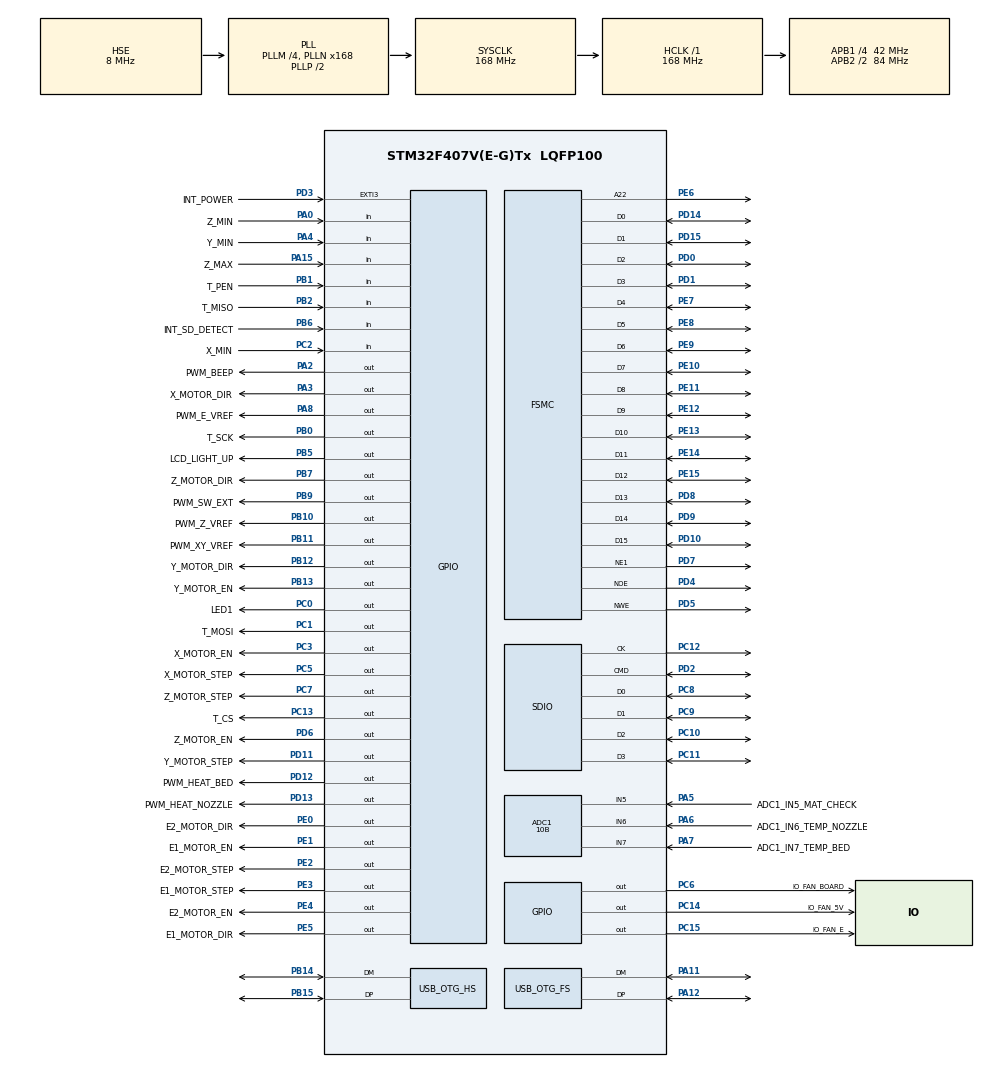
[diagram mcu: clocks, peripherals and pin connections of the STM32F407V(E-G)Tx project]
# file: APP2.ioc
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ADC1.Channel-0\#ChannelRegularConversion=ADC_CHANNEL_5
ADC1.EnableAnalogWatchDog=false
ADC1.NbrOfConversionFlag=1
ADC1.Rank-0\#ChannelRegularConversion=1
ADC1.Resolution=ADC_RESOLUTION_10B
ADC1.SamplingTime-0\#ChannelRegularConversion=ADC_SAMPLETIME_3CYCLES
ADC1.ScanConvMode=ENABLE
ADC1.master=1
Dma.Request0=SDIO_RX
Dma.Request1=SDIO_TX
Dma.SDIO_RX.0.Direction=DMA_PERIPH_TO_MEMORY
Dma.SDIO_RX.0.FIFOMode=DMA_FIFOMODE_ENABLE
Dma.SDIO_RX.0.FIFOThreshold=DMA_FIFO_THRESHOLD_FULL
Dma.SDIO_RX.0.Instance=DMA2_Stream3
Dma.SDIO_RX.0.MemBurst=DMA_MBURST_INC4
Dma.SDIO_RX.0.MemDataAlignment=DMA_MDATAALIGN_WORD
Dma.SDIO_RX.0.MemInc=DMA_MINC_ENABLE
Dma.SDIO_RX.0.Mode=DMA_PFCTRL
Dma.SDIO_RX.0.PeriphBurst=DMA_PBURST_INC4
Dma.SDIO_RX.0.PeriphDataAlignment=DMA_PDATAALIGN_WORD
Dma.SDIO_RX.0.PeriphInc=DMA_PINC_DISABLE
Dma.SDIO_RX.0.Priority=DMA_PRIORITY_LOW
Dma.SDIO_TX.1.Direction=DMA_MEMORY_TO_PERIPH
Dma.SDIO_TX.1.FIFOMode=DMA_FIFOMODE_ENABLE
Dma.SDIO_TX.1.FIFOThreshold=DMA_FIFO_THRESHOLD_FULL
Dma.SDIO_TX.1.Instance=DMA2_Stream6
Dma.SDIO_TX.1.MemBurst=DMA_MBURST_INC4
Dma.SDIO_TX.1.MemDataAlignment=DMA_MDATAALIGN_WORD
Dma.SDIO_TX.1.MemInc=DMA_MINC_ENABLE
Dma.SDIO_TX.1.Mode=DMA_PFCTRL
Dma.SDIO_TX.1.PeriphBurst=DMA_PBURST_INC4
Dma.SDIO_TX.1.PeriphDataAlignment=DMA_PDATAALIGN_WORD
Dma.SDIO_TX.1.PeriphInc=DMA_PINC_DISABLE
Dma.SDIO_TX.1.Priority=DMA_PRIORITY_LOW
FATFS.BSP.number=1
FATFS._CODE_PAGE=936
FATFS._FS_LOCK=16
FATFS._FS_NORTC=0
FATFS._MAX_LFN=64
FATFS._USE_LFN=3
FATFS0.BSP.STBoard=false
FATFS0.BSP.i2caddr=0
FATFS0.BSP.i2creg=0
FATFS0.BSP.instance=PB6
FATFS0.BSP.ip=GPIO
FATFS0.BSP.mode=Input
FATFS0.BSP.name=Detect_SDIO
FSMC.BusTurnAroundDuration1=0
FSMC.DataSetupTime1=60
FSMC.ExtendedAddressSetupTime1=9
FSMC.ExtendedBusTurnAroundDuration1=0
FSMC.ExtendedDataSetupTime1=8
FSMC.ExtendedMode1=FSMC_EXTENDED_MODE_ENABLE
Mcu.Family=STM32F4
Mcu.Name=STM32F407V(E-G)Tx
Mcu.Package=LQFP100
NVIC.ADC_IRQn=true\:0\:0\:false\:true\:true\:5
NVIC.DMA2_Stream3_IRQn=true\:8\:0\:true\:true\:true\:9
NVIC.DMA2_Stream6_IRQn=true\:8\:0\:true\:true\:true\:11
NVIC.EXTI3_IRQn=true\:0\:0\:false\:true\:true\:4
NVIC.FLASH_IRQn=true\:0\:0\:false\:true\:true\:2
NVIC.FPU_IRQn=true\:0\:0\:false\:true\:true\:15
NVIC.OTG_FS_IRQn=true\:7\:0\:true\:true\:true\:10
NVIC.OTG_HS_EP1_IN_IRQn=true\:7\:0\:true\:true\:true\:13
NVIC.OTG_HS_EP1_OUT_IRQn=true\:7\:0\:true\:true\:true\:12
NVIC.OTG_HS_IRQn=true\:7\:0\:true\:true\:true\:14
NVIC.PVD_IRQn=true\:0\:0\:false\:true\:true\:1
NVIC.PriorityGroup=NVIC_PRIORITYGROUP_4
NVIC.RCC_IRQn=true\:0\:0\:false\:true\:true\:3
NVIC.SDIO_IRQn=true\:7\:0\:true\:true\:true\:8
NVIC.TIM1_UP_TIM10_IRQn=true\:0\:0\:false\:false\:true
NVIC.TimeBase=TIM1_UP_TIM10_IRQn
NVIC.TimeBaseIP=TIM1
PA0-WKUP.GPIO_Label=Z_MIN
PA0-WKUP.GPIO_PuPd=GPIO_PULLUP
PA0-WKUP.Signal=GPIO_Input
PA11.GPIO_Speed=GPIO_SPEED_FREQ_VERY_HIGH
PA11.Mode=Host_Only
PA11.Signal=USB_OTG_FS_DM
PA12.GPIO_Speed=GPIO_SPEED_FREQ_VERY_HIGH
PA12.Mode=Host_Only
PA12.Signal=USB_OTG_FS_DP
PA15.GPIO_Label=Z_MAX
PA15.GPIO_PuPd=GPIO_PULLUP
PA15.Signal=GPIO_Input
PA2.GPIO_Label=PWM_BEEP
PA2.Signal=GPIO_Output
PA3.GPIO_Label=X_MOTOR_DIR
PA3.Signal=GPIO_Output
PA4.GPIO_Label=Y_MIN
PA4.GPIO_PuPd=GPIO_PULLUP
PA4.Signal=GPIO_Input
PA5.GPIO_Label=ADC1_IN5_MAT_CHECK
PA5.Signal=ADCx_IN5
PA6.GPIO_Label=ADC1_IN6_TEMP_NOZZLE
PA6.Signal=ADCx_IN6
PA7.GPIO_Label=ADC1_IN7_TEMP_BED
PA7.Signal=ADCx_IN7
PA8.GPIO_Label=PWM_E_VREF
PA8.Signal=GPIO_Output
PB0.GPIO_Label=T_SCK
PB0.Signal=GPIO_Output
PB1.GPIO_Label=T_PEN
PB1.Signal=GPIO_Input
PB10.GPIO_Label=PWM_Z_VREF
PB10.Signal=GPIO_Output
PB11.GPIO_Label=PWM_XY_VREF
PB11.Signal=GPIO_Output
PB12.GPIO_Label=Y_MOTOR_DIR
PB12.Signal=GPIO_Output
PB13.GPIO_Label=Y_MOTOR_EN
PB13.Signal=GPIO_Output
PB14.Mode=Host_FS
PB14.Signal=USB_OTG_HS_DM
PB15.Mode=Host_FS
PB15.Signal=USB_OTG_HS_DP
PB2.GPIO_Label=T_MISO
PB2.Signal=GPIO_Input
PB5.GPIO_Label=LCD_LIGHT_UP
PB5.GPIO_PuPd=GPIO_PULLUP
PB5.Signal=GPIO_Output
PB6.GPIO_Label=INT_SD_DETECT
PB6.GPIO_PuPd=GPIO_PULLUP
PB6.Signal=GPIO_Input
PB7.GPIO_Label=Z_MOTOR_DIR
PB7.Signal=GPIO_Output
PB9.GPIO_Label=PWM_SW_EXT
PB9.Signal=GPIO_Output
PC0.GPIO_Label=LED1
PC0.GPIO_PuPd=GPIO_PULLUP
PC0.Signal=GPIO_Output
PC1.GPIO_Label=T_MOSI
PC1.Signal=GPIO_Output
PC10.GPIO_PuPd=GPIO_PULLUP
PC10.GPIO_Speed_High_Default=GPIO_SPEED_FREQ_HIGH
PC10.Mode=SD_4_bits_Wide_bus
PC10.Signal=SDIO_D2
PC11.GPIO_PuPd=GPIO_PULLUP
PC11.GPIO_Speed_High_Default=GPIO_SPEED_FREQ_HIGH
PC11.Mode=SD_4_bits_Wide_bus
PC11.Signal=SDIO_D3
PC12.GPIO_Speed_High_Default=GPIO_SPEED_FREQ_HIGH
PC12.Mode=SD_4_bits_Wide_bus
PC12.Signal=SDIO_CK
PC13-ANTI_TAMP.GPIO_Label=T_CS
PC13-ANTI_TAMP.Signal=GPIO_Output
PC14-OSC32_IN.GPIO_Label=IO_FAN_5V
PC14-OSC32_IN.Signal=GPIO_Output
PC15-OSC32_OUT.GPIO_Label=IO_FAN_E
PC15-OSC32_OUT.Signal=GPIO_Output
PC2.GPIO_Label=X_MIN
PC2.GPIO_PuPd=GPIO_PULLUP
PC2.Signal=GPIO_Input
PC3.GPIO_Label=X_MOTOR_EN
PC3.Signal=GPIO_Output
PC5.GPIO_Label=X_MOTOR_STEP
PC5.Signal=GPIO_Output
PC6.GPIO_Label=IO_FAN_BOARD
PC6.Signal=GPIO_Output
PC7.GPIO_Label=Z_MOTOR_STEP
PC7.Signal=GPIO_Output
PC8.GPIO_PuPd=GPIO_PULLUP
PC8.GPIO_Speed_High_Default=GPIO_SPEED_FREQ_HIGH
PC8.Mode=SD_4_bits_Wide_bus
PC8.Signal=SDIO_D0
PC9.GPIO_PuPd=GPIO_PULLUP
PC9.GPIO_Speed_High_Default=GPIO_SPEED_FREQ_HIGH
PC9.Mode=SD_4_bits_Wide_bus
PC9.Signal=SDIO_D1
PD0.Mode=16b-d1
PD0.Signal=FSMC_D2
PD1.Mode=16b-d1
PD1.Signal=FSMC_D3
PD10.Mode=16b-d1
PD10.Signal=FSMC_D15
PD11.GPIO_Label=Y_MOTOR_STEP
PD11.Signal=GPIO_Output
PD12.GPIO_Label=PWM_HEAT_BED
PD12.Signal=GPIO_Output
PD13.GPIO_Label=PWM_HEAT_NOZZLE
PD13.Signal=GPIO_Output
PD14.Mode=16b-d1
PD14.Signal=FSMC_D0
PD15.Mode=16b-d1
PD15.Signal=FSMC_D1
PD2.GPIO_PuPd=GPIO_PULLUP
PD2.GPIO_Speed_High_Default=GPIO_SPEED_FREQ_HIGH
PD2.Mode=SD_4_bits_Wide_bus
PD2.Signal=SDIO_CMD
PD3.GPIO_Label=INT_POWER
PD3.GPIO_PuPd=GPIO_PULLUP
PD3.Signal=GPXTI3
PD4.Mode=Lcd1
PD4.Signal=FSMC_NOE
PD5.Mode=Lcd1
PD5.Signal=FSMC_NWE
PD6.GPIO_Label=Z_MOTOR_EN
PD6.Signal=GPIO_Output
PD7.Mode=NorPsramChipSelect1_1
PD7.Signal=FSMC_NE1
PD8.Mode=16b-d1
PD8.Signal=FSMC_D13
PD9.Mode=16b-d1
PD9.Signal=FSMC_D14
PE0.GPIO_Label=E2_MOTOR_DIR
PE0.Signal=GPIO_Output
PE1.GPIO_Label=E1_MOTOR_EN
PE1.Signal=GPIO_Output
PE10.Mode=16b-d1
PE10.Signal=FSMC_D7
PE11.Mode=16b-d1
PE11.Signal=FSMC_D8
PE12.Mode=16b-d1
PE12.Signal=FSMC_D9
PE13.Mode=16b-d1
PE13.Signal=FSMC_D10
PE14.Mode=16b-d1
PE14.Signal=FSMC_D11
PE15.Mode=16b-d1
PE15.Signal=FSMC_D12
PE2.GPIO_Label=E2_MOTOR_STEP
PE2.Signal=GPIO_Output
PE3.GPIO_Label=E1_MOTOR_STEP
PE3.Signal=GPIO_Output
PE4.GPIO_Label=E2_MOTOR_EN
PE4.Signal=GPIO_Output
PE5.GPIO_Label=E1_MOTOR_DIR
PE5.Signal=GPIO_Output
PE6.Mode=A22_1
PE6.Signal=FSMC_A22
PE7.Mode=16b-d1
PE7.Signal=FSMC_D4
PE8.Mode=16b-d1
PE8.Signal=FSMC_D5
PE9.Mode=16b-d1
PE9.Signal=FSMC_D6
PH0-OSC_IN.Mode=HSE-External-Oscillator
PH0-OSC_IN.Signal=RCC_OSC_IN
PH1-OSC_OUT.Mode=HSE-External-Oscillator
PH1-OSC_OUT.Signal=RCC_OSC_OUT
ProjectManager.HeapSize=0x2000
ProjectManager.StackSize=0x2000
ProjectManager.TargetToolchain=MDK-ARM V5
RCC.48MHZClocksFreq_Value=48000000
RCC.AHBFreq_Value=168000000
RCC.APB1CLKDivider=RCC_HCLK_DIV4
RCC.APB1Freq_Value=42000000
RCC.APB1TimFreq_Value=84000000
RCC.APB2CLKDivider=RCC_HCLK_DIV2
RCC.APB2Freq_Value=84000000
RCC.APB2TimFreq_Value=168000000
RCC.CortexFreq_Value=168000000
RCC.HCLKFreq_Value=168000000
RCC.HSE_VALUE=8000000
RCC.HSI_VALUE=16000000
RCC.LSE_VALUE=32768
RCC.PLLM=4
RCC.PLLN=168
RCC.PLLQ=7
RCC.SYSCLKFreq_VALUE=168000000
RCC.SYSCLKSource=RCC_SYSCLKSOURCE_PLLCLK
RCC.VCOOutputFreq_Value=336000000
SDIO.BusWide=SDIO_BUS_WIDE_1B
SDIO.ClockDiv=1
SDIO.WideMode=SDIO_BUS_WIDE_4B
SH.ADCx_IN5.0=ADC1_IN5,IN5
SH.ADCx_IN6.0=ADC1_IN6,IN6
SH.ADCx_IN7.0=ADC1_IN7,IN7
USB_HOST.USBH_HandleTypeDef-MSC_FS=hUsbHostFS
USB_HOST.USBH_PROCESS_STACK_SIZE-MSC_FS=640
USB_HOST.VirtualModeFS=Msc
USB_OTG_FS.phy_itface=HCD_PHY_EMBEDDED
USB_OTG_HS.VirtualMode-Host_FS=Host_FS
USB_OTG_HS.dma_enable-Host_FS=ENABLE
VP_CRC_VS_CRC.Mode=CRC_Activate
VP_FATFS_VS_SDIO.Mode=SDIO
VP_FATFS_VS_USB.Mode=USB
VP_SYS_VS_tim1.Mode=TIM1
VP_USB_HOST_VS_USB_HOST_MSC_FS.Mode=MSC_FS
board=APP2

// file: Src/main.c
/**
  ******************************************************************************
  * File Name          : main.c
  * Description        : Main program body
  ******************************************************************************
  *
  * COPYRIGHT(c) 2016 STMicroelectronics
  *
  * Redistribution and use in source and binary forms, with or without modification,
  * are permitted provided that the following conditions are met:
  *   1. Redistributions of source code must retain the above copyright notice,
  *      this list of conditions and the following disclaimer.
  *   2. Redistributions in binary form must reproduce the above copyright notice,
  *      this list of conditions and the following disclaimer in the documentation
  *      and/or other materials provided with the distribution.
  *   3. Neither the name of STMicroelectronics nor the names of its contributors
  *      may be used to endorse or promote products derived from this software
  *      without specific prior written permission.
  *
  * THIS SOFTWARE IS PROVIDED BY THE COPYRIGHT HOLDERS AND CONTRIBUTORS "AS IS"
  * AND ANY EXPRESS OR IMPLIED WARRANTIES, INCLUDING, BUT NOT LIMITED TO, THE
  * IMPLIED WARRANTIES OF MERCHANTABILITY AND FITNESS FOR A PARTICULAR PURPOSE ARE
  * DISCLAIMED. IN NO EVENT SHALL THE COPYRIGHT HOLDER OR CONTRIBUTORS BE LIABLE
  * FOR ANY DIRECT, INDIRECT, INCIDENTAL, SPECIAL, EXEMPLARY, OR CONSEQUENTIAL
  * DAMAGES (INCLUDING, BUT NOT LIMITED TO, PROCUREMENT OF SUBSTITUTE GOODS OR
  * SERVICES; LOSS OF USE, DATA, OR PROFITS; OR BUSINESS INTERRUPTION) HOWEVER
  * CAUSED AND ON ANY THEORY OF LIABILITY, WHETHER IN CONTRACT, STRICT LIABILITY,
  * OR TORT (INCLUDING NEGLIGENCE OR OTHERWISE) ARISING IN ANY WAY OUT OF THE USE
  * OF THIS SOFTWARE, EVEN IF ADVISED OF THE POSSIBILITY OF SUCH DAMAGE.
  *
  ******************************************************************************
  */
#include "stm32f4xx_hal.h"
#include "fatfs.h"
#include "usb_host.h"

/* USER CODE BEGIN Includes */
#include "lcd.h"
#include "iap_menu.h"
/* USER CODE END Includes */

ADC_HandleTypeDef hadc1;

CRC_HandleTypeDef hcrc;

SD_HandleTypeDef hsd;
HAL_SD_CardInfoTypedef SDCardInfo;
DMA_HandleTypeDef hdma_sdio_rx;
DMA_HandleTypeDef hdma_sdio_tx;

HCD_HandleTypeDef hhcd_USB_OTG_HS;

SRAM_HandleTypeDef hsram1;

/* USER CODE BEGIN PV */
/* Private variables ---------------------------------------------------------*/

/* USER CODE END PV */

void SystemClock_Config(void);
void Error_Handler(void);
static void MX_GPIO_Init(void);
static void MX_DMA_Init(void);
static void MX_SDIO_SD_Init(void);
static void MX_FSMC_Init(void);
static void MX_ADC1_Init(void);
static void MX_USB_OTG_HS_HCD_Init(void);
static void MX_CRC_Init(void);
static void MX_NVIC_Init(void);
void MX_USB_HOST_Process(void);

/* USER CODE BEGIN PFP */
/* Private function prototypes -----------------------------------------------*/

/* USER CODE END PFP */

/* USER CODE BEGIN 0 */
void BoardInit(void)
{
  //解锁电机
  HAL_GPIO_WritePin(X_MOTOR_EN_GPIO_Port, X_MOTOR_EN_Pin, GPIO_PIN_SET);
  HAL_GPIO_WritePin(Y_MOTOR_EN_GPIO_Port, Y_MOTOR_EN_Pin, GPIO_PIN_SET);
  HAL_GPIO_WritePin(Z_MOTOR_EN_GPIO_Port, Z_MOTOR_EN_Pin, GPIO_PIN_SET);
  HAL_GPIO_WritePin(E1_MOTOR_EN_GPIO_Port, E1_MOTOR_EN_Pin, GPIO_PIN_SET);
  HAL_GPIO_WritePin(E2_MOTOR_EN_GPIO_Port, E2_MOTOR_EN_Pin, GPIO_PIN_SET);

  //关闭加热
  HAL_GPIO_WritePin(PWM_HEAT_BED_GPIO_Port, PWM_HEAT_BED_Pin, GPIO_PIN_RESET);
  HAL_GPIO_WritePin(PWM_HEAT_NOZZLE_GPIO_Port, PWM_HEAT_NOZZLE_Pin, GPIO_PIN_RESET);
  HAL_GPIO_WritePin(PWM_SW_EXT_GPIO_Port, PWM_SW_EXT_Pin, GPIO_PIN_RESET);
}

void APP_LCD_Init(void)
{
  LCD_Init(); //LCD初始化
  HAL_Delay(50);
  HAL_GPIO_WritePin(LCD_LIGHT_UP_GPIO_Port, LCD_LIGHT_UP_Pin, GPIO_PIN_SET); //点亮液晶屏
  POINT_COLOR = (uint16_t)WHITE;
}

unsigned int TextPosition_y = 20;
void APP_LCD_ShowString(uint8_t *p, uint8_t isNextLine)
{
  if(isNextLine) TextPosition_y += 30;
  LCD_ShowString(80, TextPosition_y, 320, 24, 24, p);
}

void APP_LCD_Clear(uint16_t color)
{
  LCD_Clear(color);
  TextPosition_y = 20;
}

/* USER CODE END 0 */

int main(void)
{

  /* MCU Configuration----------------------------------------------------------*/

  /* Reset of all peripherals, Initializes the Flash interface and the Systick. */
  HAL_Init();

  /* Configure the system clock */
  SystemClock_Config();

  /* Initialize all configured peripherals */
  MX_GPIO_Init();
  MX_DMA_Init();
  MX_FATFS_Init();
  MX_USB_HOST_Init();
  MX_SDIO_SD_Init();
  MX_FSMC_Init();
  MX_ADC1_Init();
  MX_USB_OTG_HS_HCD_Init();
  MX_CRC_Init();

  /* Initialize interrupts */
  MX_NVIC_Init();

  /* USER CODE BEGIN 2 */
  BoardInit();

  // 挂载SD卡和U盘
  SDCard_Mount();
  USBDisk_Mount();

  APP_LCD_Init();
  APP_LCD_Clear(BLACK);
  APP_LCD_ShowString((uint8_t *)"Start Bootloader...", 0);
  /* USER CODE END 2 */

  /* Infinite loop */
  while (1)
  {
    MX_USB_HOST_Process();

  }

}

/** System Clock Configuration
*/
void SystemClock_Config(void)
{

  RCC_OscInitTypeDef RCC_OscInitStruct;
  RCC_ClkInitTypeDef RCC_ClkInitStruct;

  __HAL_RCC_PWR_CLK_ENABLE();

  __HAL_PWR_VOLTAGESCALING_CONFIG(PWR_REGULATOR_VOLTAGE_SCALE1);

  RCC_OscInitStruct.OscillatorType = RCC_OSCILLATORTYPE_HSE;
  RCC_OscInitStruct.HSEState = RCC_HSE_ON;
  RCC_OscInitStruct.PLL.PLLState = RCC_PLL_ON;
  RCC_OscInitStruct.PLL.PLLSource = RCC_PLLSOURCE_HSE;
  RCC_OscInitStruct.PLL.PLLM = 4;
  RCC_OscInitStruct.PLL.PLLN = 168;
  RCC_OscInitStruct.PLL.PLLP = RCC_PLLP_DIV2;
  RCC_OscInitStruct.PLL.PLLQ = 7;
  if (HAL_RCC_OscConfig(&RCC_OscInitStruct) != HAL_OK)
  {
    Error_Handler();
  }

  RCC_ClkInitStruct.ClockType = RCC_CLOCKTYPE_HCLK|RCC_CLOCKTYPE_SYSCLK
                                |RCC_CLOCKTYPE_PCLK1|RCC_CLOCKTYPE_PCLK2;
  RCC_ClkInitStruct.SYSCLKSource = RCC_SYSCLKSOURCE_PLLCLK;
  RCC_ClkInitStruct.AHBCLKDivider = RCC_SYSCLK_DIV1;
  RCC_ClkInitStruct.APB1CLKDivider = RCC_HCLK_DIV4;
  RCC_ClkInitStruct.APB2CLKDivider = RCC_HCLK_DIV2;
  if (HAL_RCC_ClockConfig(&RCC_ClkInitStruct, FLASH_LATENCY_5) != HAL_OK)
  {
    Error_Handler();
  }

  HAL_SYSTICK_Config(HAL_RCC_GetHCLKFreq()/1000);

  HAL_SYSTICK_CLKSourceConfig(SYSTICK_CLKSOURCE_HCLK);

  /* SysTick_IRQn interrupt configuration */
  HAL_NVIC_SetPriority(SysTick_IRQn, 0, 0);
}

/** NVIC Configuration
*/
static void MX_NVIC_Init(void)
{
  /* PVD_IRQn interrupt configuration */
  HAL_NVIC_SetPriority(PVD_IRQn, 0, 0);
  HAL_NVIC_EnableIRQ(PVD_IRQn);
  /* FLASH_IRQn interrupt configuration */
  HAL_NVIC_SetPriority(FLASH_IRQn, 0, 0);
  HAL_NVIC_EnableIRQ(FLASH_IRQn);
  /* RCC_IRQn interrupt configuration */
  HAL_NVIC_SetPriority(RCC_IRQn, 0, 0);
  HAL_NVIC_EnableIRQ(RCC_IRQn);
  /* EXTI3_IRQn interrupt configuration */
  HAL_NVIC_SetPriority(EXTI3_IRQn, 0, 0);
  HAL_NVIC_EnableIRQ(EXTI3_IRQn);
  /* ADC_IRQn interrupt configuration */
  HAL_NVIC_SetPriority(ADC_IRQn, 0, 0);
  HAL_NVIC_EnableIRQ(ADC_IRQn);
  /* SDIO_IRQn interrupt configuration */
  HAL_NVIC_SetPriority(SDIO_IRQn, 7, 0);
  HAL_NVIC_EnableIRQ(SDIO_IRQn);
  /* DMA2_Stream3_IRQn interrupt configuration */
  HAL_NVIC_SetPriority(DMA2_Stream3_IRQn, 8, 0);
  HAL_NVIC_EnableIRQ(DMA2_Stream3_IRQn);
  /* OTG_FS_IRQn interrupt configuration */
  HAL_NVIC_SetPriority(OTG_FS_IRQn, 7, 0);
  HAL_NVIC_EnableIRQ(OTG_FS_IRQn);
  /* DMA2_Stream6_IRQn interrupt configuration */
  HAL_NVIC_SetPriority(DMA2_Stream6_IRQn, 8, 0);
  HAL_NVIC_EnableIRQ(DMA2_Stream6_IRQn);
  /* OTG_HS_EP1_OUT_IRQn interrupt configuration */
  HAL_NVIC_SetPriority(OTG_HS_EP1_OUT_IRQn, 7, 0);
  HAL_NVIC_EnableIRQ(OTG_HS_EP1_OUT_IRQn);
  /* OTG_HS_EP1_IN_IRQn interrupt configuration */
  HAL_NVIC_SetPriority(OTG_HS_EP1_IN_IRQn, 7, 0);
  HAL_NVIC_EnableIRQ(OTG_HS_EP1_IN_IRQn);
  /* OTG_HS_IRQn interrupt configuration */
  HAL_NVIC_SetPriority(OTG_HS_IRQn, 7, 0);
  HAL_NVIC_EnableIRQ(OTG_HS_IRQn);
  /* FPU_IRQn interrupt configuration */
  HAL_NVIC_SetPriority(FPU_IRQn, 0, 0);
  HAL_NVIC_EnableIRQ(FPU_IRQn);
}

/* ADC1 init function */
static void MX_ADC1_Init(void)
{

  ADC_ChannelConfTypeDef sConfig;

  /**Configure the global features of the ADC (Clock, Resolution, Data Alignment and number of conversion)
  */
  hadc1.Instance = ADC1;
  hadc1.Init.ClockPrescaler = ADC_CLOCK_SYNC_PCLK_DIV4;
  hadc1.Init.Resolution = ADC_RESOLUTION_10B;
  hadc1.Init.ScanConvMode = ENABLE;
  hadc1.Init.ContinuousConvMode = DISABLE;
  hadc1.Init.DiscontinuousConvMode = DISABLE;
  hadc1.Init.ExternalTrigConvEdge = ADC_EXTERNALTRIGCONVEDGE_NONE;
  hadc1.Init.DataAlign = ADC_DATAALIGN_RIGHT;
  hadc1.Init.NbrOfConversion = 1;
  hadc1.Init.DMAContinuousRequests = DISABLE;
  hadc1.Init.EOCSelection = ADC_EOC_SINGLE_CONV;
  if (HAL_ADC_Init(&hadc1) != HAL_OK)
  {
    Error_Handler();
  }

  /**Configure for the selected ADC regular channel its corresponding rank in the sequencer and its sample time.
  */
  sConfig.Channel = ADC_CHANNEL_5;
  sConfig.Rank = 1;
  sConfig.SamplingTime = ADC_SAMPLETIME_3CYCLES;
  if (HAL_ADC_ConfigChannel(&hadc1, &sConfig) != HAL_OK)
  {
    Error_Handler();
  }

}

/* CRC init function */
static void MX_CRC_Init(void)
{

  hcrc.Instance = CRC;
  if (HAL_CRC_Init(&hcrc) != HAL_OK)
  {
    Error_Handler();
  }

}

/* SDIO init function */
static void MX_SDIO_SD_Init(void)
{

  hsd.Instance = SDIO;
  hsd.Init.ClockEdge = SDIO_CLOCK_EDGE_RISING;
  hsd.Init.ClockBypass = SDIO_CLOCK_BYPASS_DISABLE;
  hsd.Init.ClockPowerSave = SDIO_CLOCK_POWER_SAVE_DISABLE;
  hsd.Init.BusWide = SDIO_BUS_WIDE_1B;
  hsd.Init.HardwareFlowControl = SDIO_HARDWARE_FLOW_CONTROL_DISABLE;
  hsd.Init.ClockDiv = 1;

}

/* USB_OTG_HS init function */
static void MX_USB_OTG_HS_HCD_Init(void)
{

  hhcd_USB_OTG_HS.Instance = USB_OTG_HS;
  hhcd_USB_OTG_HS.Init.dev_endpoints = 6;
  hhcd_USB_OTG_HS.Init.Host_channels = 12;
  hhcd_USB_OTG_HS.Init.speed = HCD_SPEED_FULL;
  hhcd_USB_OTG_HS.Init.dma_enable = ENABLE;
  hhcd_USB_OTG_HS.Init.phy_itface = USB_OTG_EMBEDDED_PHY;
  hhcd_USB_OTG_HS.Init.Sof_enable = DISABLE;
  hhcd_USB_OTG_HS.Init.low_power_enable = DISABLE;
  hhcd_USB_OTG_HS.Init.vbus_sensing_enable = DISABLE;
  hhcd_USB_OTG_HS.Init.use_external_vbus = DISABLE;
  if (HAL_HCD_Init(&hhcd_USB_OTG_HS) != HAL_OK)
  {
    Error_Handler();
  }

}

static void MX_DMA_Init(void)
{
  /* DMA controller clock enable */
  __HAL_RCC_DMA2_CLK_ENABLE();

}

/** Configure pins as
        * Analog
        * Input
        * Output
        * EVENT_OUT
        * EXTI
*/
static void MX_GPIO_Init(void)
{

  GPIO_InitTypeDef GPIO_InitStruct;

  /* GPIO Ports Clock Enable */
  __HAL_RCC_GPIOE_CLK_ENABLE();
  __HAL_RCC_GPIOC_CLK_ENABLE();
  __HAL_RCC_GPIOH_CLK_ENABLE();
  __HAL_RCC_GPIOA_CLK_ENABLE();
  __HAL_RCC_GPIOB_CLK_ENABLE();
  __HAL_RCC_GPIOD_CLK_ENABLE();

  /*Configure GPIO pin Output Level */
  HAL_GPIO_WritePin(GPIOE, E2_MOTOR_STEP_Pin|E1_MOTOR_STEP_Pin|E2_MOTOR_EN_Pin|E1_MOTOR_DIR_Pin
                    |E2_MOTOR_DIR_Pin|E1_MOTOR_EN_Pin, GPIO_PIN_RESET);

  /*Configure GPIO pin Output Level */
  HAL_GPIO_WritePin(GPIOC, T_CS_Pin|IO_FAN_5V_Pin|IO_FAN_E_Pin|LED1_Pin
                    |T_MOSI_Pin|X_MOTOR_EN_Pin|X_MOTOR_STEP_Pin|IO_FAN_BOARD_Pin
                    |Z_MOTOR_STEP_Pin, GPIO_PIN_RESET);

  /*Configure GPIO pin Output Level */
  HAL_GPIO_WritePin(GPIOA, PWM_BEEP_Pin|X_MOTOR_DIR_Pin|PWM_E_VREF_Pin, GPIO_PIN_RESET);

  /*Configure GPIO pin Output Level */
  HAL_GPIO_WritePin(GPIOB, T_SCK_Pin|PWM_Z_VREF_Pin|PWM_XY_VREF_Pin|Y_MOTOR_DIR_Pin
                    |Y_MOTOR_EN_Pin|LCD_LIGHT_UP_Pin|Z_MOTOR_DIR_Pin|PWM_SW_EXT_Pin, GPIO_PIN_RESET);

  /*Configure GPIO pin Output Level */
  HAL_GPIO_WritePin(GPIOD, Y_MOTOR_STEP_Pin|PWM_HEAT_BED_Pin|PWM_HEAT_NOZZLE_Pin|Z_MOTOR_EN_Pin, GPIO_PIN_RESET);

  /*Configure GPIO pins : E2_MOTOR_STEP_Pin E1_MOTOR_STEP_Pin E2_MOTOR_EN_Pin E1_MOTOR_DIR_Pin
                           E2_MOTOR_DIR_Pin E1_MOTOR_EN_Pin */
  GPIO_InitStruct.Pin = E2_MOTOR_STEP_Pin|E1_MOTOR_STEP_Pin|E2_MOTOR_EN_Pin|E1_MOTOR_DIR_Pin
                        |E2_MOTOR_DIR_Pin|E1_MOTOR_EN_Pin;
  GPIO_InitStruct.Mode = GPIO_MODE_OUTPUT_PP;
  GPIO_InitStruct.Pull = GPIO_NOPULL;
  GPIO_InitStruct.Speed = GPIO_SPEED_FREQ_LOW;
  HAL_GPIO_Init(GPIOE, &GPIO_InitStruct);

  /*Configure GPIO pins : T_CS_Pin IO_FAN_5V_Pin IO_FAN_E_Pin T_MOSI_Pin
                           X_MOTOR_EN_Pin X_MOTOR_STEP_Pin IO_FAN_BOARD_Pin Z_MOTOR_STEP_Pin */
  GPIO_InitStruct.Pin = T_CS_Pin|IO_FAN_5V_Pin|IO_FAN_E_Pin|T_MOSI_Pin
                        |X_MOTOR_EN_Pin|X_MOTOR_STEP_Pin|IO_FAN_BOARD_Pin|Z_MOTOR_STEP_Pin;
  GPIO_InitStruct.Mode = GPIO_MODE_OUTPUT_PP;
  GPIO_InitStruct.Pull = GPIO_NOPULL;
  GPIO_InitStruct.Speed = GPIO_SPEED_FREQ_LOW;
  HAL_GPIO_Init(GPIOC, &GPIO_InitStruct);

  /*Configure GPIO pin : LED1_Pin */
  GPIO_InitStruct.Pin = LED1_Pin;
  GPIO_InitStruct.Mode = GPIO_MODE_OUTPUT_PP;
  GPIO_InitStruct.Pull = GPIO_PULLUP;
  GPIO_InitStruct.Speed = GPIO_SPEED_FREQ_LOW;
  HAL_GPIO_Init(LED1_GPIO_Port, &GPIO_InitStruct);

  /*Configure GPIO pin : X_MIN_Pin */
  GPIO_InitStruct.Pin = X_MIN_Pin;
  GPIO_InitStruct.Mode = GPIO_MODE_INPUT;
  GPIO_InitStruct.Pull = GPIO_PULLUP;
  HAL_GPIO_Init(X_MIN_GPIO_Port, &GPIO_InitStruct);

  /*Configure GPIO pins : Z_MIN_Pin Y_MIN_Pin Z_MAX_Pin */
  GPIO_InitStruct.Pin = Z_MIN_Pin|Y_MIN_Pin|Z_MAX_Pin;
  GPIO_InitStruct.Mode = GPIO_MODE_INPUT;
  GPIO_InitStruct.Pull = GPIO_PULLUP;
  HAL_GPIO_Init(GPIOA, &GPIO_InitStruct);

  /*Configure GPIO pins : PWM_BEEP_Pin X_MOTOR_DIR_Pin PWM_E_VREF_Pin */
  GPIO_InitStruct.Pin = PWM_BEEP_Pin|X_MOTOR_DIR_Pin|PWM_E_VREF_Pin;
  GPIO_InitStruct.Mode = GPIO_MODE_OUTPUT_PP;
  GPIO_InitStruct.Pull = GPIO_NOPULL;
  GPIO_InitStruct.Speed = GPIO_SPEED_FREQ_LOW;
  HAL_GPIO_Init(GPIOA, &GPIO_InitStruct);

  /*Configure GPIO pins : T_SCK_Pin PWM_Z_VREF_Pin PWM_XY_VREF_Pin Y_MOTOR_DIR_Pin
                           Y_MOTOR_EN_Pin Z_MOTOR_DIR_Pin PWM_SW_EXT_Pin */
  GPIO_InitStruct.Pin = T_SCK_Pin|PWM_Z_VREF_Pin|PWM_XY_VREF_Pin|Y_MOTOR_DIR_Pin
                        |Y_MOTOR_EN_Pin|Z_MOTOR_DIR_Pin|PWM_SW_EXT_Pin;
  GPIO_InitStruct.Mode = GPIO_MODE_OUTPUT_PP;
  GPIO_InitStruct.Pull = GPIO_NOPULL;
  GPIO_InitStruct.Speed = GPIO_SPEED_FREQ_LOW;
  HAL_GPIO_Init(GPIOB, &GPIO_InitStruct);

  /*Configure GPIO pins : T_PEN_Pin T_MISO_Pin */
  GPIO_InitStruct.Pin = T_PEN_Pin|T_MISO_Pin;
  GPIO_InitStruct.Mode = GPIO_MODE_INPUT;
  GPIO_InitStruct.Pull = GPIO_NOPULL;
  HAL_GPIO_Init(GPIOB, &GPIO_InitStruct);

  /*Configure GPIO pins : Y_MOTOR_STEP_Pin PWM_HEAT_BED_Pin PWM_HEAT_NOZZLE_Pin Z_MOTOR_EN_Pin */
  GPIO_InitStruct.Pin = Y_MOTOR_STEP_Pin|PWM_HEAT_BED_Pin|PWM_HEAT_NOZZLE_Pin|Z_MOTOR_EN_Pin;
  GPIO_InitStruct.Mode = GPIO_MODE_OUTPUT_PP;
  GPIO_InitStruct.Pull = GPIO_NOPULL;
  GPIO_InitStruct.Speed = GPIO_SPEED_FREQ_LOW;
  HAL_GPIO_Init(GPIOD, &GPIO_InitStruct);

  /*Configure GPIO pin : INT_POWER_Pin */
  GPIO_InitStruct.Pin = INT_POWER_Pin;
  GPIO_InitStruct.Mode = GPIO_MODE_IT_RISING;
  GPIO_InitStruct.Pull = GPIO_PULLUP;
  HAL_GPIO_Init(INT_POWER_GPIO_Port, &GPIO_InitStruct);

  /*Configure GPIO pin : LCD_LIGHT_UP_Pin */
  GPIO_InitStruct.Pin = LCD_LIGHT_UP_Pin;
  GPIO_InitStruct.Mode = GPIO_MODE_OUTPUT_PP;
  GPIO_InitStruct.Pull = GPIO_PULLUP;
  GPIO_InitStruct.Speed = GPIO_SPEED_FREQ_LOW;
  HAL_GPIO_Init(LCD_LIGHT_UP_GPIO_Port, &GPIO_InitStruct);

  /*Configure GPIO pin : INT_SD_DETECT_Pin */
  GPIO_InitStruct.Pin = INT_SD_DETECT_Pin;
  GPIO_InitStruct.Mode = GPIO_MODE_INPUT;
  GPIO_InitStruct.Pull = GPIO_PULLUP;
  HAL_GPIO_Init(INT_SD_DETECT_GPIO_Port, &GPIO_InitStruct);

}

/* FSMC initialization function */
static void MX_FSMC_Init(void)
{
  FSMC_NORSRAM_TimingTypeDef Timing;
  FSMC_NORSRAM_TimingTypeDef ExtTiming;

  /** Perform the SRAM1 memory initialization sequence
  */
  hsram1.Instance = FSMC_NORSRAM_DEVICE;
  hsram1.Extended = FSMC_NORSRAM_EXTENDED_DEVICE;
  /* hsram1.Init */
  hsram1.Init.NSBank = FSMC_NORSRAM_BANK1;
  hsram1.Init.DataAddressMux = FSMC_DATA_ADDRESS_MUX_DISABLE;
  hsram1.Init.MemoryType = FSMC_MEMORY_TYPE_SRAM;
  hsram1.Init.MemoryDataWidth = FSMC_NORSRAM_MEM_BUS_WIDTH_16;
  hsram1.Init.BurstAccessMode = FSMC_BURST_ACCESS_MODE_DISABLE;
  hsram1.Init.WaitSignalPolarity = FSMC_WAIT_SIGNAL_POLARITY_LOW;
  hsram1.Init.WrapMode = FSMC_WRAP_MODE_DISABLE;
  hsram1.Init.WaitSignalActive = FSMC_WAIT_TIMING_BEFORE_WS;
  hsram1.Init.WriteOperation = FSMC_WRITE_OPERATION_ENABLE;
  hsram1.Init.WaitSignal = FSMC_WAIT_SIGNAL_DISABLE;
  hsram1.Init.ExtendedMode = FSMC_EXTENDED_MODE_ENABLE;
  hsram1.Init.AsynchronousWait = FSMC_ASYNCHRONOUS_WAIT_DISABLE;
  hsram1.Init.WriteBurst = FSMC_WRITE_BURST_DISABLE;
  hsram1.Init.PageSize = FSMC_PAGE_SIZE_NONE;
  /* Timing */
  Timing.AddressSetupTime = 15;
  Timing.AddressHoldTime = 15;
  Timing.DataSetupTime = 60;
  Timing.BusTurnAroundDuration = 0;
  Timing.CLKDivision = 16;
  Timing.DataLatency = 17;
  Timing.AccessMode = FSMC_ACCESS_MODE_A;
  /* ExtTiming */
  ExtTiming.AddressSetupTime = 9;
  ExtTiming.AddressHoldTime = 15;
  ExtTiming.DataSetupTime = 8;
  ExtTiming.BusTurnAroundDuration = 0;
  ExtTiming.CLKDivision = 16;
  ExtTiming.DataLatency = 17;
  ExtTiming.AccessMode = FSMC_ACCESS_MODE_A;

  if (HAL_SRAM_Init(&hsram1, &Timing, &ExtTiming) != HAL_OK)
  {
    Error_Handler();
  }

}

void HAL_TIM_PeriodElapsedCallback(TIM_HandleTypeDef *htim)
{
  if (htim->Instance == TIM1)
  {
    HAL_IncTick();
  }
}

void Error_Handler(void)
{
  while(1)
  {
  }
}

/************************ (C) COPYRIGHT STMicroelectronics *****END OF FILE****/
